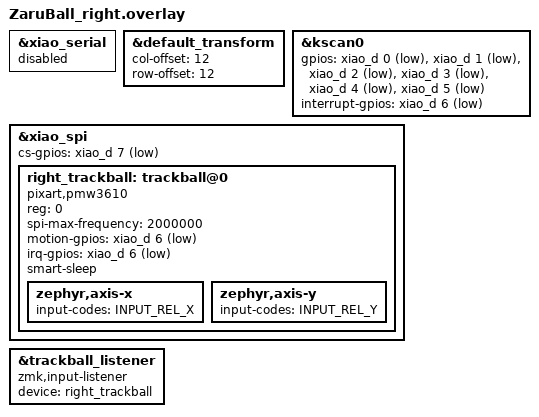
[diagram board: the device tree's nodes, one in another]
#include "ZaruBall.dtsi"
#include <input/processors.dtsi>
#include <dt-bindings/zmk/input_transform.h>
// ★修正1: 以下のヘッダーを追加（これが無いと INPUT_REL_X が使えません）
#include <dt-bindings/input/input-event-codes.h>

&xiao_serial { status = "disabled"; };

// matrix transformでのピン数オフセット
&default_transform {
    col-offset = <12>;
    row-offset = <12>;
};

&kscan0 {
    // V3.2に合わせて ACTIVE_LOW
    gpios
        = <&xiao_d 0 GPIO_ACTIVE_LOW> // M1
        , <&xiao_d 1 GPIO_ACTIVE_LOW> // M2
        , <&xiao_d 2 GPIO_ACTIVE_LOW> // M3
        , <&xiao_d 3 GPIO_ACTIVE_LOW> // M4
        , <&xiao_d 4 GPIO_ACTIVE_LOW> // M5
        , <&xiao_d 5 GPIO_ACTIVE_LOW> // M6
        ;
    // トラックボールの割り込みピン
    interrupt-gpios = <&xiao_d 6 (GPIO_ACTIVE_LOW | GPIO_PULL_UP)>;
};

&xiao_spi {
    status = "okay";
    cs-gpios = <&xiao_d 7 GPIO_ACTIVE_LOW>;

    right_trackball: trackball@0 {
        status = "okay";
        compatible = "pixart,pmw3610";
        reg = <0>;
        spi-max-frequency = <2000000>;

        // 必須設定: 動き検知ピン
        motion-gpios = <&xiao_d 6 (GPIO_ACTIVE_LOW | GPIO_PULL_UP)>;
        // 念のため irq も残す
        irq-gpios = <&xiao_d 6 (GPIO_ACTIVE_LOW | GPIO_PULL_UP)>;
        
        smart-sleep; 

        // ★修正2: 軸の中身を具体的に記述（これでエラーが消えます）
        zephyr,axis-x { 
            input-codes = <INPUT_REL_X>;
        };
        zephyr,axis-y { 
            input-codes = <INPUT_REL_Y>;
        };
    };
};

&trackball_listener {
    status = "okay";
    compatible = "zmk,input-listener";
    device = <&right_trackball>;
};
